VERSION "2.0"

BU_: ECU Dashboard Backup

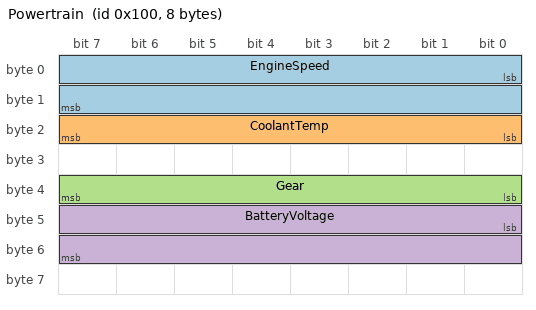
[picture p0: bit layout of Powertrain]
BO_ 256 Powertrain: 8 ECU
 SG_ EngineSpeed : 0|16@1+ (0.25,0) [0|16000] "rpm" Dashboard
 SG_ CoolantTemp : 23|8@0- (1,-40) [-40|215] "degC" Dashboard
 SG_ Gear : 32|8@1+ (1,0) [0|7] "" Dashboard
 SG_ BatteryVoltage : 40|16@1+ (0.01,0) [0|655.35] "V" Dashboard

BO_ 2147483939 ExtendedStatus: 1 ECU
 SG_ State : 0|8@1+ (1,0) [0|255] "" Dashboard

BO_ 300 Measurements: 4 ECU
 SG_ Acceleration : 0|32@1+ (1,0) [-1000|1000] "m/s2" Dashboard

SIG_VALTYPE_ 300 Acceleration : 1;

BO_TX_BU_ 2147483939 : ECU,Backup;

CM_ BO_ 256 "Powertrain status";

VAL_ 256 Gear 0 "Neutral" 1 "Drive" 2 "Reverse";
